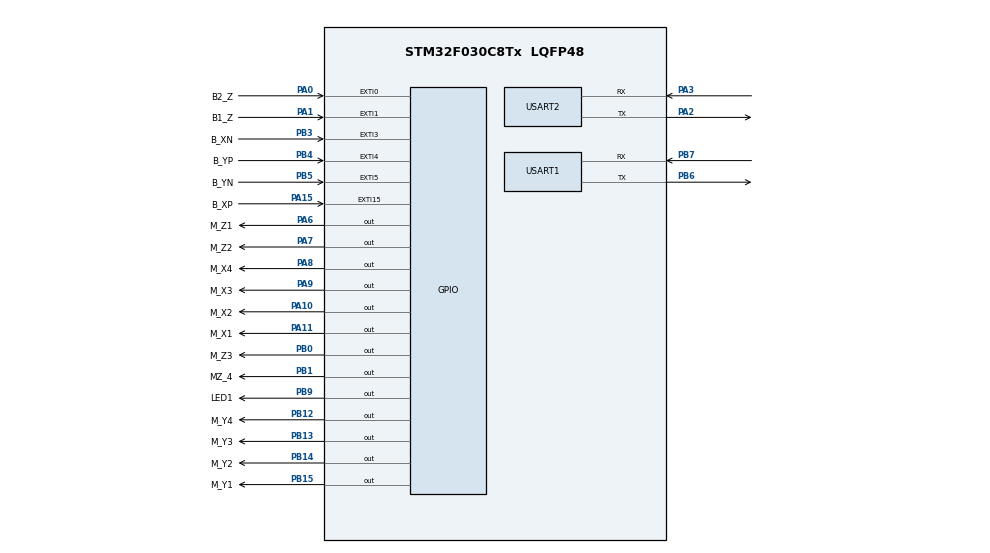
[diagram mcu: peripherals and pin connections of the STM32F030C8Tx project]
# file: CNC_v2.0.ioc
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Mcu.Family=STM32F0
Mcu.Name=STM32F030C8Tx
Mcu.Package=LQFP48
NVIC.EXTI0_1_IRQn=true\:2\:0\:true\:false\:true\:true\:true\:true
NVIC.EXTI2_3_IRQn=true\:2\:0\:true\:false\:true\:true\:true\:true
NVIC.EXTI4_15_IRQn=true\:2\:0\:true\:false\:true\:true\:true\:true
NVIC.USART1_IRQn=true\:3\:0\:true\:false\:true\:true\:true\:true
NVIC.USART2_IRQn=true\:3\:0\:true\:false\:true\:true\:true\:true
PA0.GPIO_Label=B2_Z
PA0.GPIO_PuPd=GPIO_PULLUP
PA0.Signal=GPXTI0
PA1.GPIO_Label=B1_Z
PA1.GPIO_PuPd=GPIO_PULLUP
PA1.Signal=GPXTI1
PA10.GPIO_Label=M_X2
PA10.GPIO_Speed=GPIO_SPEED_FREQ_MEDIUM
PA10.Signal=GPIO_Output
PA11.GPIO_Label=M_X1
PA11.GPIO_Speed=GPIO_SPEED_FREQ_MEDIUM
PA11.Signal=GPIO_Output
PA13.Mode=Serial_Wire
PA13.Signal=SYS_SWDIO
PA14.Mode=Serial_Wire
PA14.Signal=SYS_SWCLK
PA15.GPIO_Label=B_XP
PA15.GPIO_PuPd=GPIO_PULLUP
PA15.Signal=GPXTI15
PA2.Mode=Asynchronous
PA2.Signal=USART2_TX
PA3.Mode=Asynchronous
PA3.Signal=USART2_RX
PA6.GPIO_Label=M_Z1
PA6.GPIO_Speed=GPIO_SPEED_FREQ_MEDIUM
PA6.Signal=GPIO_Output
PA7.GPIO_Label=M_Z2
PA7.GPIO_Speed=GPIO_SPEED_FREQ_MEDIUM
PA7.Signal=GPIO_Output
PA8.GPIO_Label=M_X4
PA8.GPIO_Speed=GPIO_SPEED_FREQ_MEDIUM
PA8.Signal=GPIO_Output
PA9.GPIO_Label=M_X3
PA9.GPIO_Speed=GPIO_SPEED_FREQ_MEDIUM
PA9.Signal=GPIO_Output
PB0.GPIO_Label=M_Z3
PB0.GPIO_Speed=GPIO_SPEED_FREQ_MEDIUM
PB0.Signal=GPIO_Output
PB1.GPIO_Label=MZ_4
PB1.GPIO_Speed=GPIO_SPEED_FREQ_MEDIUM
PB1.Signal=GPIO_Output
PB12.GPIO_Label=M_Y4
PB12.GPIO_Speed=GPIO_SPEED_FREQ_MEDIUM
PB12.Signal=GPIO_Output
PB13.GPIO_Label=M_Y3
PB13.GPIO_Speed=GPIO_SPEED_FREQ_MEDIUM
PB13.Signal=GPIO_Output
PB14.GPIO_Label=M_Y2
PB14.GPIO_Speed=GPIO_SPEED_FREQ_MEDIUM
PB14.Signal=GPIO_Output
PB15.GPIO_Label=M_Y1
PB15.GPIO_Speed=GPIO_SPEED_FREQ_MEDIUM
PB15.Signal=GPIO_Output
PB3.GPIO_Label=B_XN
PB3.GPIO_PuPd=GPIO_PULLUP
PB3.Signal=GPXTI3
PB4.GPIO_Label=B_YP
PB4.GPIO_PuPd=GPIO_PULLUP
PB4.Signal=GPXTI4
PB5.GPIO_Label=B_YN
PB5.GPIO_PuPd=GPIO_PULLUP
PB5.Signal=GPXTI5
PB6.Mode=Asynchronous
PB6.Signal=USART1_TX
PB7.Mode=Asynchronous
PB7.Signal=USART1_RX
PB9.GPIO_Label=LED1
PB9.GPIO_Speed=GPIO_SPEED_FREQ_MEDIUM
PB9.Signal=GPIO_Output
ProjectManager.HeapSize=0x200
ProjectManager.StackSize=0x400
ProjectManager.TargetToolchain=CMake
USART1.VirtualMode-Asynchronous=VM_ASYNC
USART2.VirtualMode-Asynchronous=VM_ASYNC
board=custom

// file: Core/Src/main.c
/* USER CODE BEGIN Header */
/**
  ******************************************************************************
  * @file           : main.c
  * @brief          : Main program body
  ******************************************************************************
  * @attention
  *
  * Copyright (c) 2026 STMicroelectronics.
  * All rights reserved.
  *
  * This software is licensed under terms that can be found in the LICENSE file
  * in the root directory of this software component.
  * If no LICENSE file comes with this software, it is provided AS-IS.
  *
  ******************************************************************************
  */
/* USER CODE END Header */
#include "main.h"
#include "usart.h"
#include "gpio.h"

/* USER CODE BEGIN Includes */
#include "CNC.h"
/* USER CODE END Includes */

/* USER CODE BEGIN PV */
CNC_t cnc;
/* USER CODE END PV */

void SystemClock_Config(void);

/* USER CODE BEGIN 0 */
void HAL_UART_RxCpltCallback(UART_HandleTypeDef *huart) {
    if (huart->Instance == USART1) CNC_UART_ISR(&cnc);
}
/* USER CODE END 0 */

int main(void)
{

  /* MCU Configuration--------------------------------------------------------*/

  /* Reset of all peripherals, Initializes the Flash interface and the Systick. */
  HAL_Init();

  /* Configure the system clock */
  SystemClock_Config();

  /* Initialize all configured peripherals */
  MX_GPIO_Init();
  MX_USART1_UART_Init();
  MX_USART2_UART_Init();
  /* USER CODE BEGIN 2 */
  CNC_Init(&cnc, CNC_STEP_MODE_8);

  /* USER CODE END 2 */

  /* Infinite loop */
  /* USER CODE BEGIN WHILE */
  while (1)
  {
    CNC_Run(&cnc);
    /* USER CODE END WHILE */

  }
}

void SystemClock_Config(void)
{
  RCC_OscInitTypeDef RCC_OscInitStruct = {0};
  RCC_ClkInitTypeDef RCC_ClkInitStruct = {0};
  RCC_PeriphCLKInitTypeDef PeriphClkInit = {0};

  /** Initializes the RCC Oscillators according to the specified parameters
  * in the RCC_OscInitTypeDef structure.
  */
  RCC_OscInitStruct.OscillatorType = RCC_OSCILLATORTYPE_HSI;
  RCC_OscInitStruct.HSIState = RCC_HSI_ON;
  RCC_OscInitStruct.HSICalibrationValue = RCC_HSICALIBRATION_DEFAULT;
  RCC_OscInitStruct.PLL.PLLState = RCC_PLL_NONE;
  if (HAL_RCC_OscConfig(&RCC_OscInitStruct) != HAL_OK)
  {
    Error_Handler();
  }

  /** Initializes the CPU, AHB and APB buses clocks
  */
  RCC_ClkInitStruct.ClockType = RCC_CLOCKTYPE_HCLK|RCC_CLOCKTYPE_SYSCLK
                              |RCC_CLOCKTYPE_PCLK1;
  RCC_ClkInitStruct.SYSCLKSource = RCC_SYSCLKSOURCE_HSI;
  RCC_ClkInitStruct.AHBCLKDivider = RCC_SYSCLK_DIV1;
  RCC_ClkInitStruct.APB1CLKDivider = RCC_HCLK_DIV1;

  if (HAL_RCC_ClockConfig(&RCC_ClkInitStruct, FLASH_LATENCY_0) != HAL_OK)
  {
    Error_Handler();
  }
  PeriphClkInit.PeriphClockSelection = RCC_PERIPHCLK_USART1;
  PeriphClkInit.Usart1ClockSelection = RCC_USART1CLKSOURCE_PCLK1;
  if (HAL_RCCEx_PeriphCLKConfig(&PeriphClkInit) != HAL_OK)
  {
    Error_Handler();
  }
}

void Error_Handler(void)
{
  __disable_irq();
  while (1)
  {
  }
}
